# LargeDummyDevice register map
File version: 1.0
A large dummy SVD file with 100 peripherals for testing purposes
Registers are 32-bit, read-write, no defined reset value unless marked. A register's access mark holds for its fields unless they carry their own. Offsets are from the block's base; lines under a group give offsets from that group; [hi:lo] are bit positions; {n}, {i} and the like mark numbered series; 'fields as' and 'values as' point back to an identical list; <NAME> marks a mode.

## Memory map
{0x3FFFF000+0x1000*n} PERIPHERAL_{n} (n=1..100)

## PERIPHERAL_1
Base 0x40000000
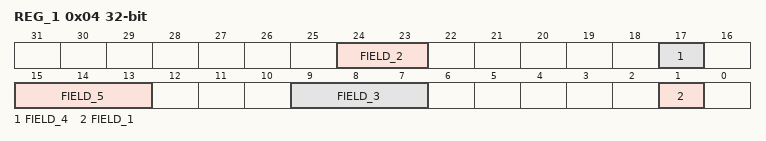
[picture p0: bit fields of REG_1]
0x04 REG_1 — Register 1
  [35:31] FIELD_2, [32:31] FIELD_7, [29] FIELD_5, [27] FIELD_12, [31:27] FIELD_15, [30:26] FIELD_9, [26] FIELD_14, [28:26] FIELD_24, [30:26] FIELD_25, [29:25] FIELD_21, [24] FIELD_8, [24:23] FIELD_1, [24:21] FIELD_4, [19:18] FIELD_6, [21:18] FIELD_16, [19:17] FIELD_26, [17:16] FIELD_17, [17:13] FIELD_19, [13:10] FIELD_18, [12:10] FIELD_22, [8:7] FIELD_10, [8:7] FIELD_20, [7:4] FIELD_3, [5:2] FIELD_11, [4:2] FIELD_13, [4:1] FIELD_23
0x08 REG_2 — Register 2
  [34:31] FIELD_3, [35:31] FIELD_11, [31:28] FIELD_12, [31:28] FIELD_13, [29:28] FIELD_14, [23] FIELD_4, [24:23] FIELD_9, [20:18] FIELD_8, [20:17] FIELD_15, [17:16] FIELD_5, [15:11] FIELD_1, [11:7] FIELD_6, [10:6] FIELD_7, [7:3] FIELD_2, [1:0] FIELD_10
0x0C REG_3 — Register 3
  [33:31] FIELD_2, [33:31] FIELD_4, [32:31] FIELD_29, [30:28] FIELD_12, [31:27] FIELD_23, [28:27] FIELD_25, [27] FIELD_32, [27:26] FIELD_3, [27:25] FIELD_13, [25] FIELD_19, [22] FIELD_30, [25:22] FIELD_31, [21:19] FIELD_6, [20:19] FIELD_21, [21:17] FIELD_8, [19:17] FIELD_15, [21:17] FIELD_18, [17:16] FIELD_16, [20:16] FIELD_24, [19:15] FIELD_1, [17:15] FIELD_5, [18:14] FIELD_28, [11] FIELD_17, [11] FIELD_22, [15:11] FIELD_26, [14:10] FIELD_10, [9] FIELD_9, [9] FIELD_11, [6] FIELD_20, [7:4] FIELD_27, [3:1] FIELD_7, [2:1] FIELD_14
0x10 REG_4 — Register 4
  [32:29] FIELD_4, [29:26] FIELD_12, [26:24] FIELD_11, [26:24] FIELD_14, [28:24] FIELD_16, [28:24] FIELD_17, [28:24] FIELD_19, [23:22] FIELD_6, [21] FIELD_8, [22:19] FIELD_7, [21:18] FIELD_18, [19:16] FIELD_5, [18:16] FIELD_13, [17:15] FIELD_20, [15:14] FIELD_10, [9] FIELD_1, [7] FIELD_3, [7:3] FIELD_9, [4:3] FIELD_15, [5:2] FIELD_2
0x14 REG_5 — Register 5
  [29] FIELD_7, [31:29] FIELD_15, [31:27] FIELD_5, [26:25] FIELD_4, [24] FIELD_11, [24] FIELD_12, [18:15] FIELD_6, [10] FIELD_8, [11:9] FIELD_9, [11:9] FIELD_13, [11:8] FIELD_1, [11:7] FIELD_3, [7] FIELD_10, [3] FIELD_14, [1] FIELD_2
0x18 REG_6 — Register 6
  [33:29] FIELD_1, [33:29] FIELD_13, [27:24] FIELD_12, [23:20] FIELD_5, [21:18] FIELD_6, [14:13] FIELD_2, [15:11] FIELD_7, [13:9] FIELD_4, [10:9] FIELD_10, [8:5] FIELD_3, [7:3] FIELD_11, [2] FIELD_9, [1:0] FIELD_8
0x1C REG_7 — Register 7
  [33:29] FIELD_3, [30:28] FIELD_6, [30:27] FIELD_1, [20] FIELD_12, [20] FIELD_15, [23:19] FIELD_4, [19:18] FIELD_5, [17:15] FIELD_8, [16:13] FIELD_7, [14:12] FIELD_14, [11] FIELD_10, [15:11] FIELD_13, [10:9] FIELD_9, [11:7] FIELD_11, [3:0] FIELD_2

## PERIPHERAL_2
Base 0x40001000
0x04 REG_1 — Register 1
  [28:27] FIELD_5, [25:22] FIELD_4, [25:21] FIELD_3, [3:2] FIELD_2, [0] FIELD_1
0x08 REG_2 — Register 2
  [32:30] FIELD_8, [28:26] FIELD_7, [25] FIELD_3, [23:19] FIELD_4, [19:18] FIELD_9, [20:17] FIELD_2, [17:16] FIELD_6, [12:9] FIELD_10, [5:1] FIELD_1, [0] FIELD_5

## PERIPHERAL_4
Base 0x40003000
0x04 REG_1 — Register 1
  [24:23] FIELD_2, [17] FIELD_4, [15:13] FIELD_5, [9:7] FIELD_3, [1] FIELD_1
0x08 REG_2 — Register 2
  [30:27] FIELD_3, [28:26] FIELD_6, [26:24] FIELD_7, [23:22] FIELD_4, [13:12] FIELD_8, [11:8] FIELD_2, [9:8] FIELD_5, [10:7] FIELD_1
0x0C REG_3 — Register 3
  [29:28] FIELD_8, [26] FIELD_4, [21:19] FIELD_2, [19:15] FIELD_1, [18:14] FIELD_6, [18:14] FIELD_7, [15:14] FIELD_9, [16:12] FIELD_3, [3] FIELD_5, [5:2] FIELD_10
0x10 REG_4 — Register 4
  [35:31] FIELD_5, [32:28] FIELD_8, [28:27] FIELD_4, [27:26] FIELD_13, [27:25] FIELD_3, [28:24] FIELD_1, [21] FIELD_6, [23:19] FIELD_9, [19] FIELD_10, [13] FIELD_2, [13] FIELD_7, [11:10] FIELD_12, [7:4] FIELD_11, [1:0] FIELD_14
0x14 REG_5 — Register 5
  [32:30] FIELD_1, [29:28] FIELD_2, [25] FIELD_3, [27:24] FIELD_7, [23:22] FIELD_4, [19:18] FIELD_5, [17:16] FIELD_6
0x18 REG_6 — Register 6
  [35:31] FIELD_2, [31:30] FIELD_4, [28] FIELD_15, [26:25] FIELD_9, [26:24] FIELD_12, [23:21] FIELD_17, [21] FIELD_20, [23:19] FIELD_18, [21:18] FIELD_5, [18:15] FIELD_7, [16:15] FIELD_10, [16:12] FIELD_16, [11] FIELD_1, [12:11] FIELD_8, [12:11] FIELD_14, [11:10] FIELD_11, [9] FIELD_13, [9:8] FIELD_3, [4:2] FIELD_19, [3:1] FIELD_6
0x1C REG_7 — Register 7
  [34:31] FIELD_3, [33:31] FIELD_13, [34:30] FIELD_10, [30:29] FIELD_22, [30:28] FIELD_11, [29:27] FIELD_12, [29:27] FIELD_25, [24:23] FIELD_26, [22] FIELD_8, [20] FIELD_1, [23:19] FIELD_23, [18:16] FIELD_9, [15:13] FIELD_15, [17:13] FIELD_20, [15:12] FIELD_7, [13:9] FIELD_18, [10:9] FIELD_24, [10:7] FIELD_6, [10:6] FIELD_14, [8:6] FIELD_21, [8:6] FIELD_27, [8:5] FIELD_2, [7:5] FIELD_4, [6:5] FIELD_19, [4:3] FIELD_17, [5:2] FIELD_16, [2:1] FIELD_5
